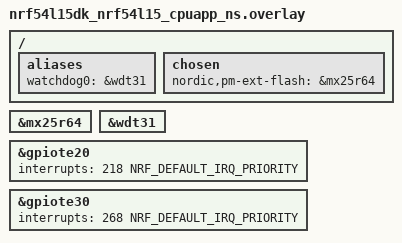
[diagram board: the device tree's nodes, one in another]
/*
 * Copyright (c) 2025 Nordic Semiconductor ASA
 *
 * SPDX-License-Identifier: LicenseRef-Nordic-5-Clause
 */

#include <samples/matter/nrf54l15_cpuapp_ns_partitions.dtsi>

/ {
	aliases {
		/* Use watchdog wdt31 as the application watchdog */
		watchdog0 = &wdt31;
	};

	chosen {
		nordic,pm-ext-flash = &mx25r64;
	};
};

&mx25r64 {
	status = "okay";
};

&wdt31 {
	status = "okay";
};

/* Change IRQ ids to handle button interrupts.
 * The default values for nRF54L15 are 219 and 269,
 * but with TF-M they are reserved for the secure domain
 * (218 and 268 are reserved for the non-secure domain).
 */
&gpiote20 {
	interrupts = <218 NRF_DEFAULT_IRQ_PRIORITY>;
};

&gpiote30 {
	interrupts = <268 NRF_DEFAULT_IRQ_PRIORITY>;
};
